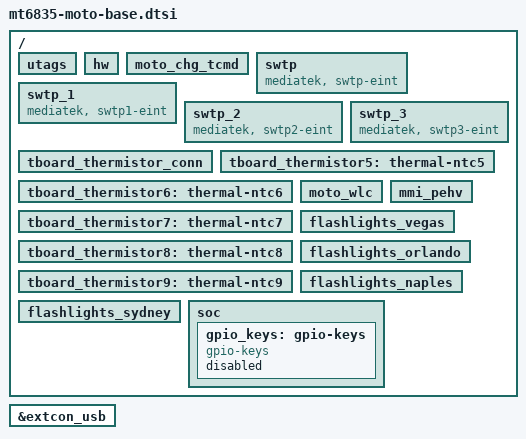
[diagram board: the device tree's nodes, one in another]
/*
 * Things can done here:
 * 	Add nodes or properties to root node
 * 	Delete nodes or properties
*/

/ {
	utags: utags { };
	hw: hw { };
	moto_chg_tcmd: moto_chg_tcmd { };
	swtp: swtp {
		compatible = "mediatek, swtp-eint";
	};
	swtp_1: swtp_1 {
		compatible = "mediatek, swtp1-eint";
	};
	swtp_2: swtp_2 {
		compatible = "mediatek, swtp2-eint";
	};
	swtp_3: swtp_3 {
		compatible = "mediatek, swtp3-eint";
	};
	tboard_thermistor_conn: tboard_thermistor_conn { };
	tboard_thermistor5: thermal-ntc5 { };
	tboard_thermistor6: thermal-ntc6 { };
	tboard_thermistor7: thermal-ntc7 { };
	tboard_thermistor8: thermal-ntc8 { };
	tboard_thermistor9: thermal-ntc9 { };
	moto_wlc: moto_wlc {};
	mmi_pehv: mmi_pehv{};
	flashlights_vegas: flashlights_vegas { };
	flashlights_orlando: flashlights_orlando { };
	flashlights_naples: flashlights_naples { };
	flashlights_sydney: flashlights_sydney { };
	soc {
		gpio_keys: gpio-keys {
			compatible = "gpio-keys";
			status = "disabled";
		};
	};

};

&extcon_usb {
	/delete-property/ vbus-supply;
};
